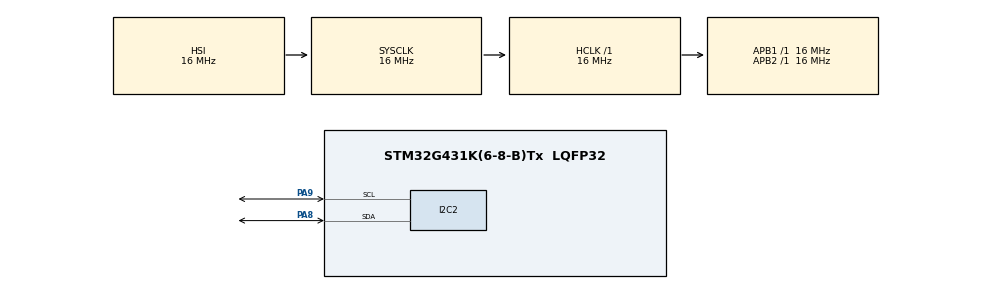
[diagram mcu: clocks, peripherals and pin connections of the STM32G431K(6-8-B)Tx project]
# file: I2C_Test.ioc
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I2C2.Timing=0x00503D58
Mcu.Family=STM32G4
Mcu.Name=STM32G431K(6-8-B)Tx
Mcu.Package=LQFP32
NVIC.PriorityGroup=NVIC_PRIORITYGROUP_4
PA13.Mode=Serial_Wire
PA13.Signal=SYS_JTMS-SWDIO
PA14.Mode=Serial_Wire
PA14.Signal=SYS_JTCK-SWCLK
PA8.Mode=I2C
PA8.Signal=I2C2_SDA
PA9.Mode=I2C
PA9.Signal=I2C2_SCL
ProjectManager.HeapSize=0x200
ProjectManager.StackSize=0x400
ProjectManager.TargetToolchain=STM32CubeIDE
RCC.AHBFreq_Value=16000000
RCC.APB1Freq_Value=16000000
RCC.APB1TimFreq_Value=16000000
RCC.APB2Freq_Value=16000000
RCC.APB2TimFreq_Value=16000000
RCC.CortexFreq_Value=16000000
RCC.EXTERNAL_CLOCK_VALUE=12288000
RCC.HCLKFreq_Value=16000000
RCC.HSE_VALUE=8000000
RCC.HSI48_VALUE=48000000
RCC.HSI_VALUE=16000000
RCC.LSE_VALUE=32768
RCC.SYSCLKFreq_VALUE=16000000
RCC.USBFreq_Value=64000000
RCC.VCOOutputFreq_Value=128000000
VP_SYS_VS_DBSignals.Mode=DisableDeadBatterySignals
board=custom

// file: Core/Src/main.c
/* USER CODE BEGIN Header */
/**
  ******************************************************************************
  * @file           : main.c
  * @brief          : Main program body
  ******************************************************************************
  */
/* USER CODE END Header */
#include "main.h"
#include "code.h" // Importation de votre fichier

I2C_HandleTypeDef hi2c2;

/* USER CODE BEGIN PV */
uint8_t found_address = 0; // Variable pour stocker l'adresse du capteur
/* USER CODE END PV */

void SystemClock_Config(void);
static void MX_GPIO_Init(void);
static void MX_I2C2_Init(void);

int main(void)
{

  HAL_Init();
  SystemClock_Config();
  MX_GPIO_Init();
  MX_I2C2_Init();

  /* USER CODE BEGIN 2 */
  // Lancement du scan I2C au démarrage
  found_address = I2C_Scan(&hi2c2);
  /* USER CODE END 2 */

  /* Infinite loop */
  while (1)
  {

  }
}

void SystemClock_Config(void)
{
  RCC_OscInitTypeDef RCC_OscInitStruct = {0};
  RCC_ClkInitTypeDef RCC_ClkInitStruct = {0};

  HAL_PWREx_ControlVoltageScaling(PWR_REGULATOR_VOLTAGE_SCALE1);
  RCC_OscInitStruct.OscillatorType = RCC_OSCILLATORTYPE_HSI;
  RCC_OscInitStruct.HSIState = RCC_HSI_ON;
  RCC_OscInitStruct.HSICalibrationValue = RCC_HSICALIBRATION_DEFAULT;
  RCC_OscInitStruct.PLL.PLLState = RCC_PLL_NONE;
  if (HAL_RCC_OscConfig(&RCC_OscInitStruct) != HAL_OK)
  {
    Error_Handler();
  }

  RCC_ClkInitStruct.ClockType = RCC_CLOCKTYPE_HCLK|RCC_CLOCKTYPE_SYSCLK
                              |RCC_CLOCKTYPE_PCLK1|RCC_CLOCKTYPE_PCLK2;
  RCC_ClkInitStruct.SYSCLKSource = RCC_SYSCLKSOURCE_HSI;
  RCC_ClkInitStruct.AHBCLKDivider = RCC_SYSCLK_DIV1;
  RCC_ClkInitStruct.APB1CLKDivider = RCC_HCLK_DIV1;
  RCC_ClkInitStruct.APB2CLKDivider = RCC_HCLK_DIV1;

  if (HAL_RCC_ClockConfig(&RCC_ClkInitStruct, FLASH_LATENCY_0) != HAL_OK)
  {
    Error_Handler();
  }
}

static void MX_I2C2_Init(void)
{
  hi2c2.Instance = I2C2;
  hi2c2.Init.Timing = 0x00503D58;
  hi2c2.Init.OwnAddress1 = 0;
  hi2c2.Init.AddressingMode = I2C_ADDRESSINGMODE_7BIT;
  hi2c2.Init.DualAddressMode = I2C_DUALADDRESS_DISABLE;
  hi2c2.Init.OwnAddress2 = 0;
  hi2c2.Init.OwnAddress2Masks = I2C_OA2_NOMASK;
  hi2c2.Init.GeneralCallMode = I2C_GENERALCALL_DISABLE;
  hi2c2.Init.NoStretchMode = I2C_NOSTRETCH_DISABLE;
  if (HAL_I2C_Init(&hi2c2) != HAL_OK)
  {
    Error_Handler();
  }
  if (HAL_I2CEx_ConfigAnalogFilter(&hi2c2, I2C_ANALOGFILTER_ENABLE) != HAL_OK)
  {
    Error_Handler();
  }
  if (HAL_I2CEx_ConfigDigitalFilter(&hi2c2, 0) != HAL_OK)
  {
    Error_Handler();
  }
}

static void MX_GPIO_Init(void)
{
  __HAL_RCC_GPIOA_CLK_ENABLE();
}

void Error_Handler(void)
{
  __disable_irq();
  while (1) { }
}
